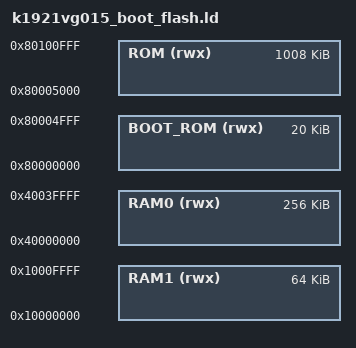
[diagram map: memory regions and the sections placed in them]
/** @file
*  @brief linker script for K1921VG015
*/

OUTPUT_ARCH( "riscv" )
ENTRY(_start)

MEMORY {
  BOOT_ROM  (rwx) : ORIGIN = 0x80000000, LENGTH = 20K
  ROM  (rwx) : ORIGIN = 0x80005000, LENGTH = 1008K
  RAM0 (rwx) : ORIGIN = 0x40000000, LENGTH = 256K
  RAM1 (rwx) : ORIGIN = 0x10000000, LENGTH = 64K
}

REGION_ALIAS("REGION_TEXT",   BOOT_ROM );
REGION_ALIAS("REGION_RODATA", BOOT_ROM );
REGION_ALIAS("REGION_DATA",   RAM0);
REGION_ALIAS("REGION_BSS",    RAM0);
REGION_ALIAS("REGION_STACK",  RAM0);
REGION_ALIAS("REGION_RAM1", RAM1);

STACK_SIZE = 4096;

INCLUDE "k1921vg015_common.lds"
